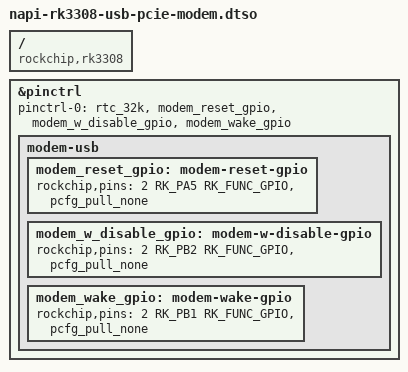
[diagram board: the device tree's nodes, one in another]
/dts-v1/;
/plugin/;

#include <dt-bindings/gpio/gpio.h>
#include <dt-bindings/pinctrl/rockchip.h>

/ {
	compatible = "rockchip,rk3308";

	fragment@0 {
		target = <&pinctrl>;
		__overlay__ {
			status = "okay";
			pinctrl-0 = <&rtc_32k &modem_reset_gpio &modem_w_disable_gpio &modem_wake_gpio>;

			modem-usb {
				modem_reset_gpio: modem-reset-gpio {
					rockchip,pins = <2 RK_PA5 RK_FUNC_GPIO &pcfg_pull_none>;
				};
				modem_w_disable_gpio: modem-w-disable-gpio {
					rockchip,pins = <2 RK_PB2 RK_FUNC_GPIO &pcfg_pull_none>;
				};
				modem_wake_gpio: modem-wake-gpio {
					rockchip,pins = <2 RK_PB1 RK_FUNC_GPIO &pcfg_pull_none>;
				};
			};
		};
	};
};
